AUTOSAR XML (schema 00046)
package /CompostionAndConnectors_Lab
  sender receiver interface SRI_LightControl
    data LightControl: type=uint32
  sender receiver interface SRI_LightAction
    data Action: type=uint32
  sensor actuator sw component type LightStatusCtrl_SWC
    provide port Pp_SRI_LightControl: provided-interface=SRI_LightControl
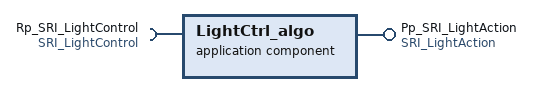
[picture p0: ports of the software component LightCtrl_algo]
  application sw component type LightCtrl_algo
    require port Rp_SRI_LightControl: required-interface=SRI_LightControl
    provide port Pp_SRI_LightAction: provided-interface=SRI_LightAction
  sensor actuator sw component type LightActuator_SWC
    require port Rp_SRI_LightAction: required-interface=SRI_LightAction
  composition sw component type SW_COMP1
    provide port Pp_External_LightAction: provided-interface=SRI_LightAction
    component LC_SR_SWC: type=LightStatusCtrl_SWC
    component Algo_SWC: type=LightCtrl_algo
    connect SW_COMP1.Pp_SRI_LightControl -> Algo_SWC.Rp_SRI_LightControl
    delegate Algo_SWC.Pp_SRI_LightAction <-> outer port Pp_External_LightAction
  composition sw component type TOP_LEVEL_COMP
    component sw_comp1_inst: type=SW_COMP1
    component LightActuator_SWC3: type=LightActuator_SWC
    connect sw_comp1_inst.Pp_External_LightAction -> LightActuator_SWC3.Rp_SRI_LightAction
